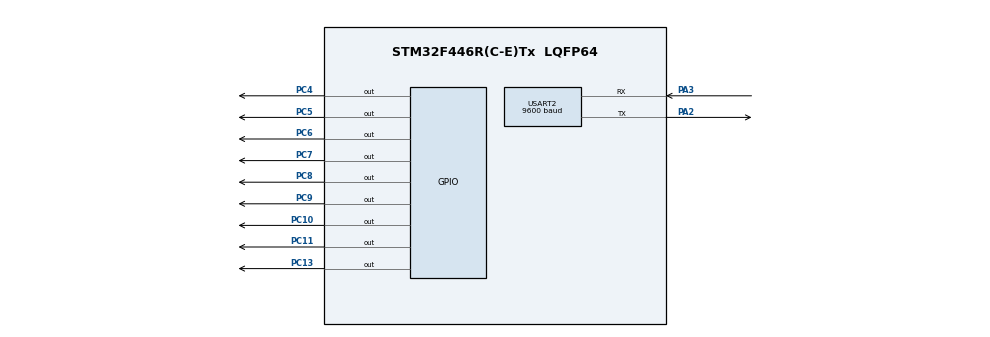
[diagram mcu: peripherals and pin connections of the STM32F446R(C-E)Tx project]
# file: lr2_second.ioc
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Mcu.Family=STM32F4
Mcu.Name=STM32F446R(C-E)Tx
Mcu.Package=LQFP64
NVIC.PriorityGroup=NVIC_PRIORITYGROUP_4
NVIC.USART2_IRQn=true\:0\:0\:false\:false\:true\:true\:true\:true
PA2.Mode=Asynchronous
PA2.Signal=USART2_TX
PA3.Mode=Asynchronous
PA3.Signal=USART2_RX
PC10.Signal=GPIO_Output
PC11.Signal=GPIO_Output
PC13.Signal=GPIO_Output
PC4.Signal=GPIO_Output
PC5.Signal=GPIO_Output
PC6.Signal=GPIO_Output
PC7.Signal=GPIO_Output
PC8.Signal=GPIO_Output
PC9.Signal=GPIO_Output
ProjectManager.HeapSize=0x200
ProjectManager.StackSize=0x400
ProjectManager.TargetToolchain=STM32CubeIDE
RCC.CortexFreq_Value=16000000
RCC.USBFreq_Value=96000000
RCC.VCOOutputFreq_Value=192000000
USART2.BaudRate=9600
USART2.VirtualMode=VM_ASYNC
board=custom

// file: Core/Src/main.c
/* USER CODE BEGIN Header */
/**
  ******************************************************************************
  * @file           : main.c
  * @brief          : Main program body
  ******************************************************************************
  * @attention
  * Copyright (c) 2024 STMicroelectronics.
  * All rights reserved.
  ******************************************************************************
  */
/* USER CODE END Header */
#include "main.h"
#include <string.h>
#include <stdio.h>

/* USER CODE BEGIN PD */
#define MAX_AMOUNT_LEDS 8
#define BUFF_SIZE 4
/* USER CODE END PD */

UART_HandleTypeDef huart2;
uint8_t RxBuffer[BUFF_SIZE];
uint8_t led_state = 0;

void SystemClock_Config(void);
static void MX_GPIO_Init(void);
static void MX_USART2_UART_Init(void);
void process_command(void);
void update_leds(void);

int main(void)
{

  /* MCU Configuration--------------------------------------------------------*/

  /* Reset of all peripherals, Initializes the Flash interface and the Systick. */
  HAL_Init();

  /* Configure the system clock */
  SystemClock_Config();

  /* Initialize all configured peripherals */
  MX_GPIO_Init();
  MX_USART2_UART_Init();
  /* USER CODE BEGIN 2 */
  HAL_UART_Receive_IT(&huart2, RxBuffer, BUFF_SIZE);

  /* USER CODE END 2 */

  /* Infinite loop */
  while (1)
  {
	  HAL_Delay(100);

  }
}

// UART Receive Complete Callback
void HAL_UART_RxCpltCallback(UART_HandleTypeDef *huart) {
if (huart->Instance == USART2) {
    process_command();  // Обрабатываем команду при получении данных
    HAL_UART_Receive_IT(&huart2, RxBuffer, BUFF_SIZE);  // Перезапускаем приём данных
}
}

// Command processing
void process_command(void) {

// Обрабатываем пакет только если начало и конец пакета совпадают с ожидаемыми значениями
if (RxBuffer[0] == 0xAA && RxBuffer[BUFF_SIZE-1] == 0xBB) {
  uint8_t TxBuffer[BUFF_SIZE];

    switch (RxBuffer[1]) {
        case 0x01:
          HAL_UART_Transmit(&huart2, RxBuffer, BUFF_SIZE, HAL_MAX_DELAY);
          break;

        case 0x02:  // Включить все светодиоды
            led_state = 0xFF;
            update_leds();
            HAL_UART_Transmit(&huart2, RxBuffer, BUFF_SIZE, HAL_MAX_DELAY);
            break;

        case 0x03:  // Выключить все светодиоды
            led_state = 0x00;
            update_leds();
            HAL_UART_Transmit(&huart2, RxBuffer, BUFF_SIZE, HAL_MAX_DELAY);
            break;

        case 0x04:  // Включить определённый набор светодиодов
            led_state = RxBuffer[2];
            update_leds();
            HAL_UART_Transmit(&huart2, RxBuffer, BUFF_SIZE, HAL_MAX_DELAY);
            break;

        case 0x05:  // Запрос состояния светодиодов
            TxBuffer[0] = 0xAA;
            TxBuffer[1] = 0x05;
            TxBuffer[2] = led_state;
            TxBuffer[3] = 0xBB;

            HAL_UART_Transmit(&huart2, TxBuffer, BUFF_SIZE, HAL_MAX_DELAY);
            break;

        default:
            break;
    }
}
}
// Update LED states
void update_leds(void) {
    for (int i = 0; i < MAX_AMOUNT_LEDS; i++) {
        if (i < led_state) {
            HAL_GPIO_WritePin(GPIOC, GPIO_PIN_4 << i, GPIO_PIN_SET);  // Включаем первые led_state светодиодов
        } else {
            HAL_GPIO_WritePin(GPIOC, GPIO_PIN_4 << i, GPIO_PIN_RESET); // Остальные выключаем
        }
    }
}

void SystemClock_Config(void)
{
  RCC_OscInitTypeDef RCC_OscInitStruct = {0};
  RCC_ClkInitTypeDef RCC_ClkInitStruct = {0};

  /** Configure the main internal regulator output voltage
  */
  __HAL_RCC_PWR_CLK_ENABLE();
  __HAL_PWR_VOLTAGESCALING_CONFIG(PWR_REGULATOR_VOLTAGE_SCALE3);

  /** Initializes the RCC Oscillators according to the specified parameters
  * in the RCC_OscInitTypeDef structure.
  */
  RCC_OscInitStruct.OscillatorType = RCC_OSCILLATORTYPE_HSI;
  RCC_OscInitStruct.HSIState = RCC_HSI_ON;
  RCC_OscInitStruct.HSICalibrationValue = RCC_HSICALIBRATION_DEFAULT;
  RCC_OscInitStruct.PLL.PLLState = RCC_PLL_NONE;
  if (HAL_RCC_OscConfig(&RCC_OscInitStruct) != HAL_OK)
  {
    Error_Handler();
  }

  /** Initializes the CPU, AHB and APB buses clocks
  */
  RCC_ClkInitStruct.ClockType = RCC_CLOCKTYPE_HCLK|RCC_CLOCKTYPE_SYSCLK
                              |RCC_CLOCKTYPE_PCLK1|RCC_CLOCKTYPE_PCLK2;
  RCC_ClkInitStruct.SYSCLKSource = RCC_SYSCLKSOURCE_HSI;
  RCC_ClkInitStruct.AHBCLKDivider = RCC_SYSCLK_DIV1;
  RCC_ClkInitStruct.APB1CLKDivider = RCC_HCLK_DIV1;
  RCC_ClkInitStruct.APB2CLKDivider = RCC_HCLK_DIV1;

  if (HAL_RCC_ClockConfig(&RCC_ClkInitStruct, FLASH_LATENCY_0) != HAL_OK)
  {
    Error_Handler();
  }
}

static void MX_USART2_UART_Init(void)
{

  huart2.Instance = USART2;
  huart2.Init.BaudRate = 9600;
  huart2.Init.WordLength = UART_WORDLENGTH_8B;
  huart2.Init.StopBits = UART_STOPBITS_1;
  huart2.Init.Parity = UART_PARITY_NONE;
  huart2.Init.Mode = UART_MODE_TX_RX;
  huart2.Init.HwFlowCtl = UART_HWCONTROL_NONE;
  huart2.Init.OverSampling = UART_OVERSAMPLING_16;
  if (HAL_UART_Init(&huart2) != HAL_OK)
  {
    Error_Handler();
  }

}

static void MX_GPIO_Init(void)
{
  GPIO_InitTypeDef GPIO_InitStruct = {0};

  /* GPIO Ports Clock Enable */
  __HAL_RCC_GPIOC_CLK_ENABLE();
  __HAL_RCC_GPIOA_CLK_ENABLE();

  /*Configure GPIO pin Output Level */
  HAL_GPIO_WritePin(GPIOC, GPIO_PIN_13|GPIO_PIN_4|GPIO_PIN_5|GPIO_PIN_6
                          |GPIO_PIN_7|GPIO_PIN_8|GPIO_PIN_9|GPIO_PIN_10
                          |GPIO_PIN_11, GPIO_PIN_RESET);

  /*Configure GPIO pins : PC13 PC4 PC5 PC6
                           PC7 PC8 PC9 PC10
                           PC11 */
  GPIO_InitStruct.Pin = GPIO_PIN_13|GPIO_PIN_4|GPIO_PIN_5|GPIO_PIN_6
                          |GPIO_PIN_7|GPIO_PIN_8|GPIO_PIN_9|GPIO_PIN_10
                          |GPIO_PIN_11;
  GPIO_InitStruct.Mode = GPIO_MODE_OUTPUT_PP;
  GPIO_InitStruct.Pull = GPIO_NOPULL;
  GPIO_InitStruct.Speed = GPIO_SPEED_FREQ_LOW;
  HAL_GPIO_Init(GPIOC, &GPIO_InitStruct);

}

void Error_Handler(void)
{
  __disable_irq();
  while (1)
  {
  }
}
